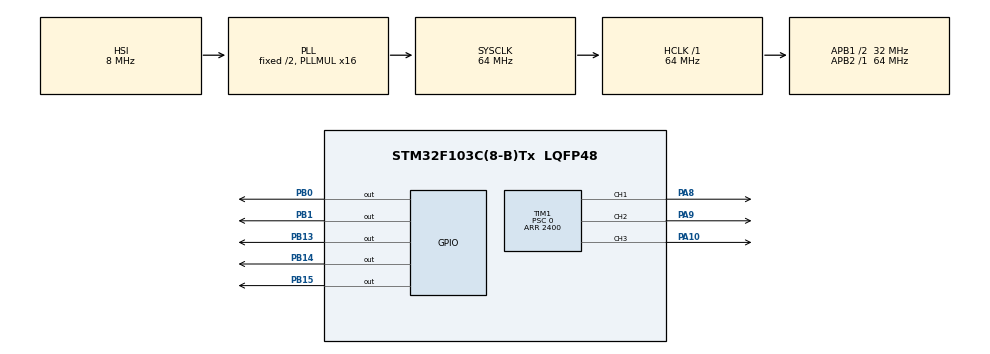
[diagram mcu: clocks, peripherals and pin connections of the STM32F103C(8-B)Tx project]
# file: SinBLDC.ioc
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Mcu.Family=STM32F1
TIM2.AutoReloadPreload=TIM_AUTORELOAD_PRELOAD_ENABLE
TIM2.Channel-Input_Capture3_from_TI3=TIM_CHANNEL_3
TIM1.CounterMode=TIM_COUNTERMODE_CENTERALIGNED3
NVIC.TIM1_UP_IRQn=true\:0\:0\:false\:false\:true\:true\:true
TIM1.Pulse-PWM\ Generation1\ CH1=0
RCC.APB1CLKDivider=RCC_HCLK_DIV2
PB13.Signal=GPIO_Output
PB15.Signal=GPIO_Output
PB15.PinState=GPIO_PIN_SET
TIM2.Channel-Input_Capture2_from_TI2=TIM_CHANNEL_2
RCC.SYSCLKSource=RCC_SYSCLKSOURCE_PLLCLK
ProjectManager.StackSize=0x400
TIM4.Channel-Input_Capture1_from_TI1=TIM_CHANNEL_1
PA13.Signal=SYS_JTMS-SWDIO
TIM1.Pulse-PWM\ Generation3\ CH3=0
TIM2.ICPolarity_CH2=TIM_INPUTCHANNELPOLARITY_RISING
PB14.PinState=GPIO_PIN_SET
TIM1.Prescaler=0
SH.S_TIM1_CH1.0=TIM1_CH1,PWM Generation1 CH1
ProjectManager.TargetToolchain=STM32CubeIDE
SH.S_TIM2_CH3.0=TIM2_CH3,Input_Capture3_from_TI3
RCC.HCLKFreq_Value=64000000
RCC.APB2TimFreq_Value=64000000
TIM2.ICFilter_CH3=4
PA9.Signal=S_TIM1_CH2
TIM2.ICFilter_CH2=4
PB6.Signal=S_TIM4_CH1
TIM1.Channel-PWM\ Generation2\ CH2=TIM_CHANNEL_2
TIM2.ICFilter_CH1=4
RCC.USBFreq_Value=42666666.666666664
TIM2.Prescaler=127
RCC.AHBFreq_Value=64000000
PB14.Signal=GPIO_Output
board=custom
RCC.PLLMUL=RCC_PLL_MUL16
RCC.APB2Freq_Value=64000000
PB13.PinState=GPIO_PIN_SET
SH.S_TIM1_CH2.0=TIM1_CH2,PWM Generation2 CH2
TIM1.Channel-PWM\ Generation1\ CH1=TIM_CHANNEL_1
PA14.Mode=Serial_Wire
SH.S_TIM2_CH2.0=TIM4_CH2,Input_Capture2_from_TI2
PB7.Signal=S_TIM4_CH2
PA8.Signal=S_TIM1_CH1
TIM2.Period=65535
PA13.Mode=Serial_Wire
Mcu.Name=STM32F103C(8-B)Tx
VP_TIM1_VS_ClockSourceINT.Mode=Internal
RCC.SYSCLKFreq_VALUE=64000000
Mcu.Package=LQFP48
PB1.Signal=GPIO_Output
TIM1.Pulse-PWM\ Generation2\ CH2=0
PA10.Signal=S_TIM1_CH3
PA14.Signal=SYS_JTCK-SWCLK
ProjectManager.HeapSize=0x200
SH.S_TIM1_CH3.0=TIM1_CH3,PWM Generation3 CH3
VP_TIM2_VS_ClockSourceINT.Mode=Internal
NVIC.PriorityGroup=NVIC_PRIORITYGROUP_4
SH.S_TIM2_CH1.0=TIM2_CH1,Input_Capture1_from_TI1
RCC.APB1TimFreq_Value=64000000
PB8.Signal=S_TIM4_CH3
TIM1.Period=2400
TIM1.Channel-PWM\ Generation3\ CH3=TIM_CHANNEL_3
NVIC.TIM2_IRQn=true\:0\:0\:false\:false\:true\:true\:true
RCC.APB1Freq_Value=32000000
PB0.Signal=GPIO_Output

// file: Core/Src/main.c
/* USER CODE BEGIN Header */
/**
  ******************************************************************************
  * @file           : main.c
  * @brief          : Main program body
  ******************************************************************************
  * @attention
  *
  * <h2><center>&copy; Copyright (c) 2020 STMicroelectronics.
  * All rights reserved.</center></h2>
  *
  * This software component is licensed by ST under BSD 3-Clause license,
  * the "License"; You may not use this file except in compliance with the
  * License. You may obtain a copy of the License at:
  *                        opensource.org/licenses/BSD-3-Clause
  *
  ******************************************************************************
  */
/* USER CODE END Header */

#include "main.h"
#include "tim.h"
#include "gpio.h"

void SystemClock_Config(void);

int main(void)
{

  /* MCU Configuration--------------------------------------------------------*/

  /* Reset of all peripherals, Initializes the Flash interface and the Systick. */
  HAL_Init();

  /* Configure the system clock */
  SystemClock_Config();

  /* Initialize all configured peripherals */
  MX_GPIO_Init();
  MX_TIM1_Init();
  MX_TIM2_Init();
  /* USER CODE BEGIN 2 */
  RunTimers();
  /* USER CODE END 2 */

  /* Infinite loop */
  /* USER CODE BEGIN WHILE */

	TIM1->CCR1 = 0;
	TIM1->CCR2 = 0;
	TIM1->CCR3 = 0;

	for(int i = 1; i <= 10; i++)
	{
		HAL_Delay(100);
		RunDrive(i, 9);
	}
	//SetHallMode(HallModeEnabled);

  while (1)
  {
    /* USER CODE END WHILE */

    /* USER CODE BEGIN 3 */
	//CalibHall(10000);
  }
  /* USER CODE END 3 */
}

void SystemClock_Config(void)
{
  RCC_OscInitTypeDef RCC_OscInitStruct = {0};
  RCC_ClkInitTypeDef RCC_ClkInitStruct = {0};

  /** Initializes the CPU, AHB and APB busses clocks
  */
  RCC_OscInitStruct.OscillatorType = RCC_OSCILLATORTYPE_HSI;
  RCC_OscInitStruct.HSIState = RCC_HSI_ON;
  RCC_OscInitStruct.HSICalibrationValue = RCC_HSICALIBRATION_DEFAULT;
  RCC_OscInitStruct.PLL.PLLState = RCC_PLL_ON;
  RCC_OscInitStruct.PLL.PLLSource = RCC_PLLSOURCE_HSI_DIV2;
  RCC_OscInitStruct.PLL.PLLMUL = RCC_PLL_MUL16;
  if (HAL_RCC_OscConfig(&RCC_OscInitStruct) != HAL_OK)
  {
    Error_Handler();
  }
  /** Initializes the CPU, AHB and APB busses clocks
  */
  RCC_ClkInitStruct.ClockType = RCC_CLOCKTYPE_HCLK|RCC_CLOCKTYPE_SYSCLK
                              |RCC_CLOCKTYPE_PCLK1|RCC_CLOCKTYPE_PCLK2;
  RCC_ClkInitStruct.SYSCLKSource = RCC_SYSCLKSOURCE_PLLCLK;
  RCC_ClkInitStruct.AHBCLKDivider = RCC_SYSCLK_DIV1;
  RCC_ClkInitStruct.APB1CLKDivider = RCC_HCLK_DIV2;
  RCC_ClkInitStruct.APB2CLKDivider = RCC_HCLK_DIV1;

  if (HAL_RCC_ClockConfig(&RCC_ClkInitStruct, FLASH_LATENCY_2) != HAL_OK)
  {
    Error_Handler();
  }
}

void Error_Handler(void)
{
}

/************************ (C) COPYRIGHT STMicroelectronics *****END OF FILE****/
